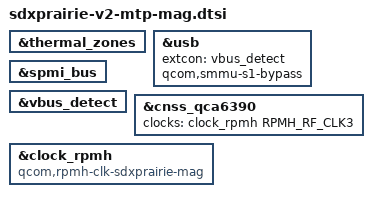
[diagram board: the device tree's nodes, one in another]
/*
 * Copyright (c) 2021, The Linux Foundation. All rights reserved.
 *
 * This program is free software; you can redistribute it and/or modify
 * it under the terms of the GNU General Public License version 2 and
 * only version 2 as published by the Free Software Foundation.
 *
 * This program is distributed in the hope that it will be useful,
 * but WITHOUT ANY WARRANTY; without even the implied warranty of
 * MERCHANTABILITY or FITNESS FOR A PARTICULAR PURPOSE.  See the
 * GNU General Public License for more details.
 */

#include "sdxprairie-v2.dtsi"
#include "sdxprairie-mtp.dtsi"
#include "sdxprairie-bluetooth-mag.dtsi"

/delete-node/ &pm8150b_fg;
/delete-node/ &pm8150b_bcl;
/delete-node/ &pm8150b_pdphy;
/delete-node/ &pm8150b_charger;
/delete-node/ &pm8150b_adc_tm;
/delete-node/ &pm8150b_vadc;

/* delete pm8150b nodes */
&thermal_zones {
	/delete-node/ pm8150b-wp-therm;
	/delete-node/ pm8150b_tz;
	/delete-node/ pm8150b-ibat-lvl0;
	/delete-node/ pm8150b-ibat-lvl1;
	/delete-node/ pm8150b-vbat-lvl0;
	/delete-node/ pm8150b-vbat-lvl1;
	/delete-node/ pm8150b-vbat-lvl2;
	/delete-node/ pm8150b-bcl-lvl0;
	/delete-node/ pm8150b-bcl-lvl1;
	/delete-node/ pm8150b-bcl-lvl2;
	/delete-node/ soc;
};

&usb {
	extcon = <&vbus_detect>;
	qcom,smmu-s1-bypass;
};

&spmi_bus {
	/delete-node/ qcom,pm8150b@2;
	/delete-node/ qcom,pm8150b@3;
};

&vbus_detect {
	status = "ok";
};

&cnss_qca6390 {
	clock-names = "rf_clk";
	clocks = <&clock_rpmh RPMH_RF_CLK3>;
};

&clock_rpmh {
	compatible = "qcom,rpmh-clk-sdxprairie-mag";
};
